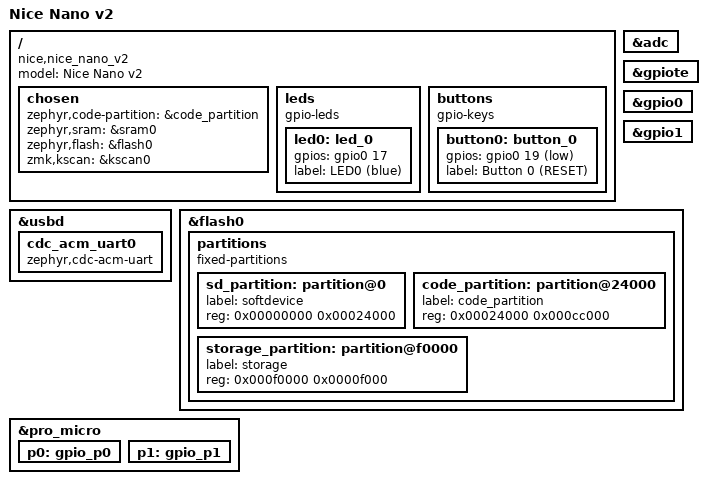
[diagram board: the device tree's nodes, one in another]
/dts-v1/;
#include <nordic/nrf52840_qiaa.dtsi>

/ {
	model = "Nice Nano v2";
	compatible = "nice,nice_nano_v2";

	chosen {
		zephyr,code-partition = &code_partition;
		zephyr,sram = &sram0;
		zephyr,flash = &flash0;
		zmk,kscan = &kscan0;
	};

	leds {
		compatible = "gpio-leds";
		led0: led_0 {
			gpios = <&gpio0 17 GPIO_ACTIVE_HIGH>;
			label = "LED0 (blue)";
		};
	};

	buttons {
		compatible = "gpio-keys";
		button0: button_0 {
			gpios = <&gpio0 19 (GPIO_PULL_UP | GPIO_ACTIVE_LOW)>;
			label = "Button 0 (RESET)";
		};
	};
};

&adc {
	status = "okay";
};

&gpiote {
	status = "okay";
};

&gpio0 {
	status = "okay";
};

&gpio1 {
	status = "okay";
};

&usbd {
	status = "okay";
	cdc_acm_uart0 {
		compatible = "zephyr,cdc-acm-uart";
	};
};

&flash0 {
	partitions {
		compatible = "fixed-partitions";
		#address-cells = <1>;
		#size-cells = <1>;

		sd_partition: partition@0 {
			label = "softdevice";
			reg = <0x00000000 0x00024000>;
		};

		code_partition: partition@24000 {
			label = "code_partition";
			reg = <0x00024000 0x000cc000>;
		};

		storage_partition: partition@f0000 {
			label = "storage";
			reg = <0x000f0000 0x0000f000>;
		};
	};
};

&pro_micro {
	status = "okay";

	p0: gpio_p0 {
		status = "okay";
	};

	p1: gpio_p1 {
		status = "okay";
	};
};
